# Espressif register map
File version: 1.0
CPU: Xtensa LX6 1, little endian, no MPU, FPU, 3 interrupt priority bits
Registers are 32-bit, access not given, reset 0x0 unless marked. A register's access mark holds for its fields unless they carry their own. Offsets are from the block's base; [hi:lo] are bit positions; {n}, {i} and the like mark numbered series.

## EFUSE
Base 0x3FF5A000
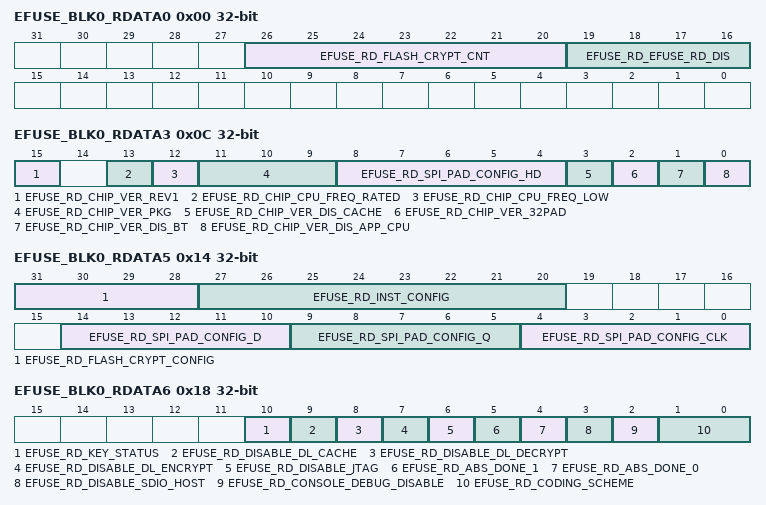
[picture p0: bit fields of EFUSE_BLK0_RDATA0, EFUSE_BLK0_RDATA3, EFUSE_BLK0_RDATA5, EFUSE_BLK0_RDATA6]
0x00 EFUSE_BLK0_RDATA0
  [26:20] EFUSE_RD_FLASH_CRYPT_CNT, [19:16] EFUSE_RD_EFUSE_RD_DIS
0x04 EFUSE_BLK0_RDATA1
  [31:0] EFUSE_RD_WIFI_MAC_CRC_LOW
0x08 EFUSE_BLK0_RDATA2
  [23:0] EFUSE_RD_WIFI_MAC_CRC_HIGH
0x0C EFUSE_BLK0_RDATA3
  [15] EFUSE_RD_CHIP_VER_REV1, [13] EFUSE_RD_CHIP_CPU_FREQ_RATED, [12] EFUSE_RD_CHIP_CPU_FREQ_LOW, [11:9] EFUSE_RD_CHIP_VER_PKG, [8:4] EFUSE_RD_SPI_PAD_CONFIG_HD, [3] EFUSE_RD_CHIP_VER_DIS_CACHE, [2] EFUSE_RD_CHIP_VER_32PAD, [1] EFUSE_RD_CHIP_VER_DIS_BT, [0] EFUSE_RD_CHIP_VER_DIS_APP_CPU
0x10 EFUSE_BLK0_RDATA4
  [16] EFUSE_RD_SDIO_FORCE, [15] EFUSE_RD_SDIO_TIEH, [14] EFUSE_RD_XPD_SDIO_REG, [13:12] EFUSE_RD_SDIO_DREFL, [11:10] EFUSE_RD_SDIO_DREFM, [12:8] EFUSE_RD_ADC_VREF, [9:8] EFUSE_RD_SDIO_DREFH, [7:0] EFUSE_RD_CK8M_FREQ
0x14 EFUSE_BLK0_RDATA5
  [31:28] EFUSE_RD_FLASH_CRYPT_CONFIG, [27:20] EFUSE_RD_INST_CONFIG, [14:10] EFUSE_RD_SPI_PAD_CONFIG_D, [9:5] EFUSE_RD_SPI_PAD_CONFIG_Q, [4:0] EFUSE_RD_SPI_PAD_CONFIG_CLK
0x18 EFUSE_BLK0_RDATA6
  [10] EFUSE_RD_KEY_STATUS, [9] EFUSE_RD_DISABLE_DL_CACHE, [8] EFUSE_RD_DISABLE_DL_DECRYPT, [7] EFUSE_RD_DISABLE_DL_ENCRYPT, [6] EFUSE_RD_DISABLE_JTAG, [5] EFUSE_RD_ABS_DONE_1, [4] EFUSE_RD_ABS_DONE_0, [3] EFUSE_RD_DISABLE_SDIO_HOST, [2] EFUSE_RD_CONSOLE_DEBUG_DISABLE, [1:0] EFUSE_RD_CODING_SCHEME
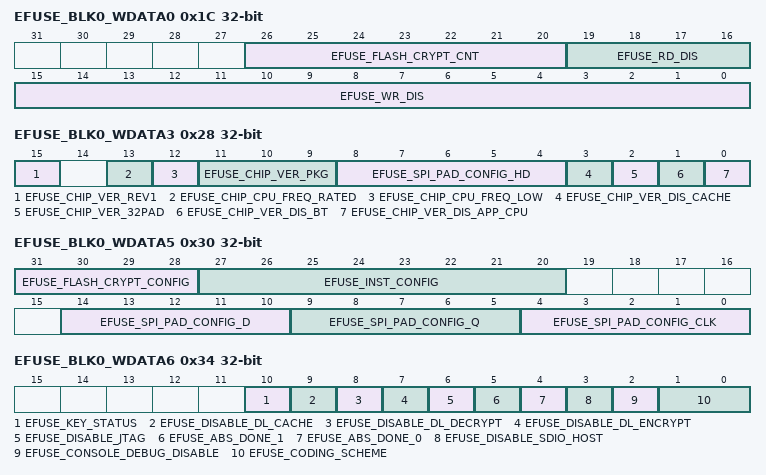
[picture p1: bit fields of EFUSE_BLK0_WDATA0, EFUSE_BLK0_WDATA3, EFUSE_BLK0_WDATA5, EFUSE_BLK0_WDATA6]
0x1C EFUSE_BLK0_WDATA0
  [26:20] EFUSE_FLASH_CRYPT_CNT, [19:16] EFUSE_RD_DIS, [15:0] EFUSE_WR_DIS
0x20 EFUSE_BLK0_WDATA1
  [31:0] EFUSE_WIFI_MAC_CRC_LOW
0x24 EFUSE_BLK0_WDATA2
  [23:0] EFUSE_WIFI_MAC_CRC_HIGH
0x28 EFUSE_BLK0_WDATA3
  [15] EFUSE_CHIP_VER_REV1, [13] EFUSE_CHIP_CPU_FREQ_RATED, [12] EFUSE_CHIP_CPU_FREQ_LOW, [11:9] EFUSE_CHIP_VER_PKG, [8:4] EFUSE_SPI_PAD_CONFIG_HD, [3] EFUSE_CHIP_VER_DIS_CACHE, [2] EFUSE_CHIP_VER_32PAD, [1] EFUSE_CHIP_VER_DIS_BT, [0] EFUSE_CHIP_VER_DIS_APP_CPU
0x2C EFUSE_BLK0_WDATA4
  [16] EFUSE_SDIO_FORCE, [15] EFUSE_SDIO_TIEH, [14] EFUSE_XPD_SDIO_REG, [13:12] EFUSE_SDIO_DREFL, [11:10] EFUSE_SDIO_DREFM, [12:8] EFUSE_ADC_VREF, [9:8] EFUSE_SDIO_DREFH, [7:0] EFUSE_CK8M_FREQ
0x30 EFUSE_BLK0_WDATA5
  [31:28] EFUSE_FLASH_CRYPT_CONFIG, [27:20] EFUSE_INST_CONFIG, [14:10] EFUSE_SPI_PAD_CONFIG_D, [9:5] EFUSE_SPI_PAD_CONFIG_Q, [4:0] EFUSE_SPI_PAD_CONFIG_CLK
0x34 EFUSE_BLK0_WDATA6
  [10] EFUSE_KEY_STATUS, [9] EFUSE_DISABLE_DL_CACHE, [8] EFUSE_DISABLE_DL_DECRYPT, [7] EFUSE_DISABLE_DL_ENCRYPT, [6] EFUSE_DISABLE_JTAG, [5] EFUSE_ABS_DONE_1, [4] EFUSE_ABS_DONE_0, [3] EFUSE_DISABLE_SDIO_HOST, [2] EFUSE_CONSOLE_DEBUG_DISABLE, [1:0] EFUSE_CODING_SCHEME
{0x38+4i} EFUSE_BLK1_RDATA{i} (i=0..7)
  [31:0] EFUSE_BLK1_DOUT{i}
{0x58+4i} EFUSE_BLK2_RDATA{i} (i=0..7)
  [31:0] EFUSE_BLK2_DOUT{i}
{0x78+4i} EFUSE_BLK3_RDATA{i} (i=0..2)
  [31:0] EFUSE_BLK3_DOUT{i}
0x84 EFUSE_BLK3_RDATA3
  [31:23] EFUSE_RD_ADC2_TP_HIGH, [22:16] EFUSE_RD_ADC2_TP_LOW, [15:7] EFUSE_RD_ADC1_TP_HIGH, [31:0] EFUSE_BLK3_DOUT3, [6:0] EFUSE_RD_ADC1_TP_LOW
{0x78+4i} EFUSE_BLK3_RDATA{i} (i=4..7)
  [31:0] EFUSE_BLK3_DOUT{i}
{0x98+4i} EFUSE_BLK1_WDATA{i} (i=0..7)
  [31:0] EFUSE_BLK1_DIN{i}
{0xB8+4i} EFUSE_BLK2_WDATA{i} (i=0..7)
  [31:0] EFUSE_BLK2_DIN{i}
{0xD8+4i} EFUSE_BLK3_WDATA{i} (i=0..2)
  [31:0] EFUSE_BLK3_DIN{i}
0xE4 EFUSE_BLK3_WDATA3
  [31:23] EFUSE_ADC2_TP_HIGH, [22:16] EFUSE_ADC2_TP_LOW, [15:7] EFUSE_ADC1_TP_HIGH, [31:0] EFUSE_BLK3_DIN3, [6:0] EFUSE_ADC1_TP_LOW
{0xD8+4i} EFUSE_BLK3_WDATA{i} (i=4..7)
  [31:0] EFUSE_BLK3_DIN{i}
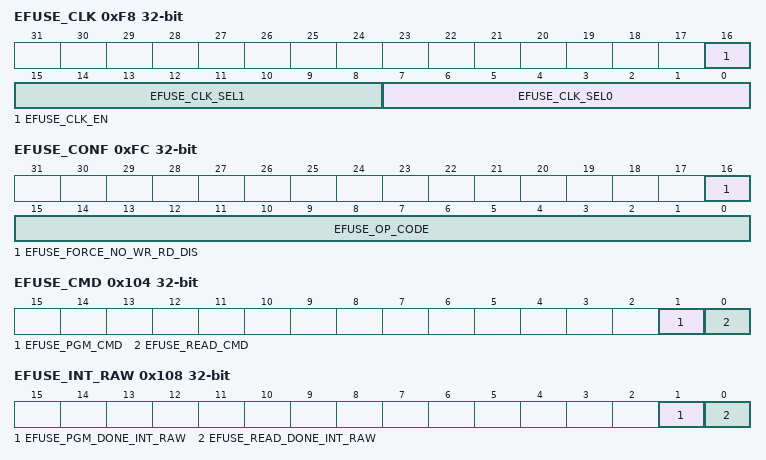
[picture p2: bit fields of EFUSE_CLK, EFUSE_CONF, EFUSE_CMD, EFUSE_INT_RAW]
0xF8 EFUSE_CLK
  [16] EFUSE_CLK_EN, [15:8] EFUSE_CLK_SEL1, [7:0] EFUSE_CLK_SEL0
0xFC EFUSE_CONF
  [16] EFUSE_FORCE_NO_WR_RD_DIS, [15:0] EFUSE_OP_CODE
0x100 EFUSE_STATUS
  [31:0] EFUSE_DEBUG
0x104 EFUSE_CMD
  [1] EFUSE_PGM_CMD, [0] EFUSE_READ_CMD
0x108 EFUSE_INT_RAW
  [1] EFUSE_PGM_DONE_INT_RAW, [0] EFUSE_READ_DONE_INT_RAW
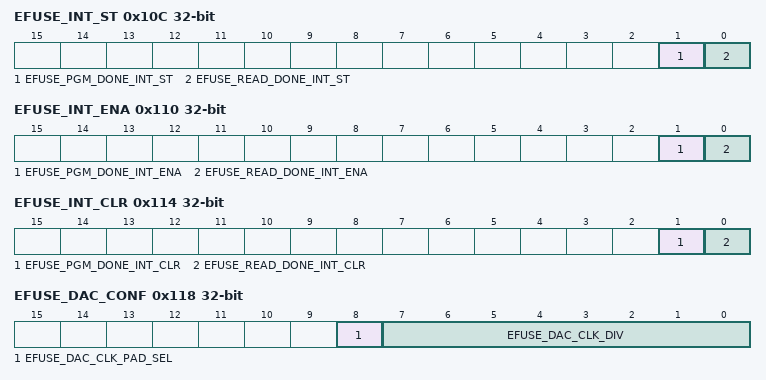
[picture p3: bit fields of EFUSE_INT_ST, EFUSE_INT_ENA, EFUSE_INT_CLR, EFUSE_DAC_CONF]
0x10C EFUSE_INT_ST
  [1] EFUSE_PGM_DONE_INT_ST, [0] EFUSE_READ_DONE_INT_ST
0x110 EFUSE_INT_ENA
  [1] EFUSE_PGM_DONE_INT_ENA, [0] EFUSE_READ_DONE_INT_ENA
0x114 EFUSE_INT_CLR
  [1] EFUSE_PGM_DONE_INT_CLR, [0] EFUSE_READ_DONE_INT_CLR
0x118 EFUSE_DAC_CONF
  [8] EFUSE_DAC_CLK_PAD_SEL, [7:0] EFUSE_DAC_CLK_DIV
0x11C EFUSE_DEC_STATUS
  [11:0] EFUSE_DEC_WARNINGS
0x1FC EFUSE_DATE
